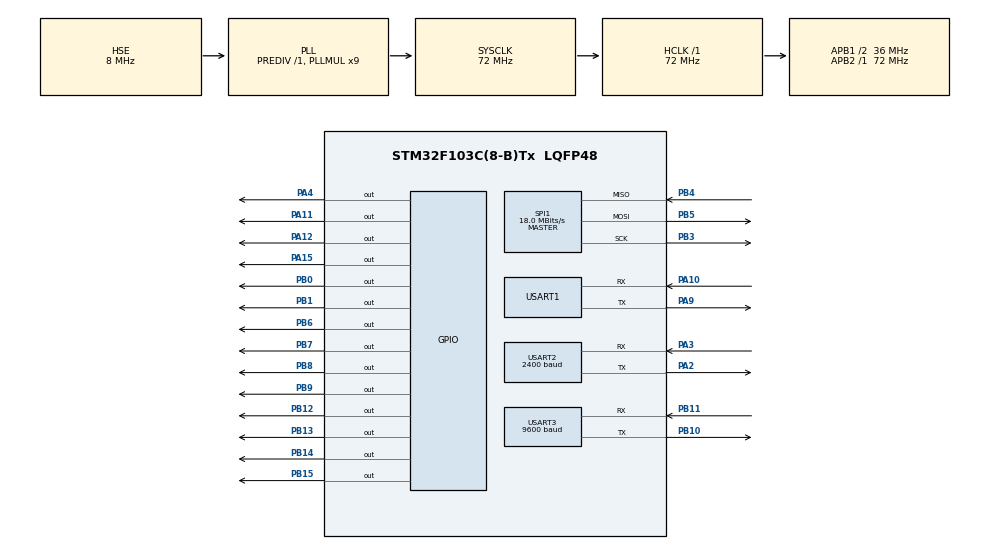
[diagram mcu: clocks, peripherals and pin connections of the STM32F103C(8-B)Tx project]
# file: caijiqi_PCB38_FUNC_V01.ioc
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Mcu.Family=STM32F1
Mcu.Name=STM32F103C(8-B)Tx
Mcu.Package=LQFP48
NVIC.PriorityGroup=NVIC_PRIORITYGROUP_2
NVIC.TIM1_UP_IRQn=true\:0\:0\:false\:false\:true\:true\:true
NVIC.USART1_IRQn=true\:0\:0\:true\:false\:true\:true\:true
NVIC.USART2_IRQn=true\:0\:0\:false\:false\:true\:true\:true
NVIC.USART3_IRQn=true\:0\:0\:false\:false\:true\:true\:true
PA10.Mode=Asynchronous
PA10.Signal=USART1_RX
PA11.Signal=GPIO_Output
PA12.Signal=GPIO_Output
PA13.Mode=Serial_Wire
PA13.Signal=SYS_JTMS-SWDIO
PA14.Mode=Serial_Wire
PA14.Signal=SYS_JTCK-SWCLK
PA15.Signal=GPIO_Output
PA2.Mode=Asynchronous
PA2.Signal=USART2_TX
PA3.Mode=Asynchronous
PA3.Signal=USART2_RX
PA4.Signal=GPIO_Output
PA9.Mode=Asynchronous
PA9.Signal=USART1_TX
PB0.Signal=GPIO_Output
PB1.Signal=GPIO_Output
PB10.Mode=Asynchronous
PB10.Signal=USART3_TX
PB11.Mode=Asynchronous
PB11.Signal=USART3_RX
PB12.Signal=GPIO_Output
PB13.Signal=GPIO_Output
PB14.GPIO_ModeDefaultOutputPP=GPIO_MODE_OUTPUT_OD
PB14.GPIO_PuPd=GPIO_PULLUP
PB14.GPIO_Speed=GPIO_SPEED_FREQ_HIGH
PB14.Signal=GPIO_Output
PB15.GPIO_ModeDefaultOutputPP=GPIO_MODE_OUTPUT_OD
PB15.GPIO_PuPd=GPIO_PULLUP
PB15.GPIO_Speed=GPIO_SPEED_FREQ_HIGH
PB15.Signal=GPIO_Output
PB3.Mode=Full_Duplex_Master
PB3.Signal=SPI1_SCK
PB4.Mode=Full_Duplex_Master
PB4.Signal=SPI1_MISO
PB5.Mode=Full_Duplex_Master
PB5.Signal=SPI1_MOSI
PB6.GPIO_Speed=GPIO_SPEED_FREQ_HIGH
PB6.PinState=GPIO_PIN_SET
PB6.Signal=GPIO_Output
PB7.GPIO_ModeDefaultOutputPP=GPIO_MODE_OUTPUT_OD
PB7.GPIO_PuPd=GPIO_PULLUP
PB7.Signal=GPIO_Output
PB8.Signal=GPIO_Output
PB9.Signal=GPIO_Output
PD0-OSC_IN.Mode=HSE-External-Oscillator
PD0-OSC_IN.Signal=RCC_OSC_IN
PD1-OSC_OUT.Mode=HSE-External-Oscillator
PD1-OSC_OUT.Signal=RCC_OSC_OUT
ProjectManager.HeapSize=0x400
ProjectManager.StackSize=0x400
ProjectManager.TargetToolchain=MDK-ARM V5
RCC.AHBFreq_Value=72000000
RCC.APB1CLKDivider=RCC_HCLK_DIV2
RCC.APB1Freq_Value=36000000
RCC.APB1TimFreq_Value=72000000
RCC.APB2Freq_Value=72000000
RCC.APB2TimFreq_Value=72000000
RCC.HCLKFreq_Value=72000000
RCC.PLLMUL=RCC_PLL_MUL9
RCC.PLLSourceVirtual=RCC_PLLSOURCE_HSE
RCC.SYSCLKFreq_VALUE=72000000
RCC.SYSCLKSource=RCC_SYSCLKSOURCE_PLLCLK
RCC.USBFreq_Value=72000000
SPI1.BaudRatePrescaler=SPI_BAUDRATEPRESCALER_4
SPI1.CLKPhase=SPI_PHASE_2EDGE
SPI1.CLKPolarity=SPI_POLARITY_HIGH
SPI1.CRCCalculation=SPI_CRCCALCULATION_DISABLE
SPI1.CalculateBaudRate=18.0 MBits/s
SPI1.Direction=SPI_DIRECTION_2LINES
SPI1.Mode=SPI_MODE_MASTER
SPI1.VirtualType=VM_MASTER
TIM1.ClockDivision=TIM_CLOCKDIVISION_DIV1
TIM1.Period=1000-1
TIM1.Prescaler=72-1
USART1.VirtualMode=VM_ASYNC
USART2.BaudRate=2400
USART2.Parity=PARITY_EVEN
USART2.VirtualMode=VM_ASYNC
USART2.WordLength=WORDLENGTH_9B
USART3.BaudRate=9600
USART3.VirtualMode=VM_ASYNC
VP_IWDG_VS_IWDG.Mode=IWDG_Activate
VP_TIM1_VS_ClockSourceINT.Mode=Internal
board=custom

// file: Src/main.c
/* USER CODE BEGIN Header */
/**
  ******************************************************************************
  * @file           : main.c
  * @brief          : Main program body
  ******************************************************************************
  * @attention
  *
  * <h2><center>&copy; Copyright (c) 2019 STMicroelectronics.
  * All rights reserved.</center></h2>
  *
  * This software component is licensed by ST under BSD 3-Clause license,
  * the "License"; You may not use this file except in compliance with the
  * License. You may obtain a copy of the License at:
  *                        opensource.org/licenses/BSD-3-Clause
  *
  ******************************************************************************
  */
/* USER CODE END Header */

#include "main.h"

IWDG_HandleTypeDef hiwdg;

SPI_HandleTypeDef hspi1;

TIM_HandleTypeDef htim1;

UART_HandleTypeDef huart1;
UART_HandleTypeDef huart2;
UART_HandleTypeDef huart3;

/* USER CODE BEGIN PV */
	void my_main(void);
/* USER CODE END PV */

void SystemClock_Config(void);
static void MX_GPIO_Init(void);
static void MX_USART1_UART_Init(void);
static void MX_USART2_UART_Init(void);
static void MX_USART3_UART_Init(void);
static void MX_SPI1_Init(void);
static void MX_TIM1_Init(void);
static void MX_IWDG_Init(void);

int main(void)
{

  /* MCU Configuration--------------------------------------------------------*/

  /* Reset of all peripherals, Initializes the Flash interface and the Systick. */
  HAL_Init();

  /* Configure the system clock */
  SystemClock_Config();

  /* Initialize all configured peripherals */
  MX_GPIO_Init();
  MX_USART1_UART_Init();
  MX_USART2_UART_Init();
  MX_USART3_UART_Init();
  MX_SPI1_Init();
  MX_TIM1_Init();
//  MX_IWDG_Init();
  /* USER CODE BEGIN 2 */
  my_main();
  /* USER CODE END 2 */

  /* Infinite loop */
  while (1)
  {

  }
}

void SystemClock_Config(void)
{
  RCC_OscInitTypeDef RCC_OscInitStruct = {0};
  RCC_ClkInitTypeDef RCC_ClkInitStruct = {0};

  /** Initializes the CPU, AHB and APB busses clocks
  */
  RCC_OscInitStruct.OscillatorType = RCC_OSCILLATORTYPE_LSI|RCC_OSCILLATORTYPE_HSE;
  RCC_OscInitStruct.HSEState = RCC_HSE_ON;
  RCC_OscInitStruct.HSEPredivValue = RCC_HSE_PREDIV_DIV1;
  RCC_OscInitStruct.HSIState = RCC_HSI_ON;
  RCC_OscInitStruct.LSIState = RCC_LSI_ON;
  RCC_OscInitStruct.PLL.PLLState = RCC_PLL_ON;
  RCC_OscInitStruct.PLL.PLLSource = RCC_PLLSOURCE_HSE;
  RCC_OscInitStruct.PLL.PLLMUL = RCC_PLL_MUL9;
  if (HAL_RCC_OscConfig(&RCC_OscInitStruct) != HAL_OK)
  {
    Error_Handler();
  }
  /** Initializes the CPU, AHB and APB busses clocks
  */
  RCC_ClkInitStruct.ClockType = RCC_CLOCKTYPE_HCLK|RCC_CLOCKTYPE_SYSCLK
                              |RCC_CLOCKTYPE_PCLK1|RCC_CLOCKTYPE_PCLK2;
  RCC_ClkInitStruct.SYSCLKSource = RCC_SYSCLKSOURCE_PLLCLK;
  RCC_ClkInitStruct.AHBCLKDivider = RCC_SYSCLK_DIV1;
  RCC_ClkInitStruct.APB1CLKDivider = RCC_HCLK_DIV2;
  RCC_ClkInitStruct.APB2CLKDivider = RCC_HCLK_DIV1;

  if (HAL_RCC_ClockConfig(&RCC_ClkInitStruct, FLASH_LATENCY_2) != HAL_OK)
  {
    Error_Handler();
  }
}

static void MX_IWDG_Init(void)
{

  hiwdg.Instance = IWDG;
  hiwdg.Init.Prescaler = IWDG_PRESCALER_4;
  hiwdg.Init.Reload = 4095;
  if (HAL_IWDG_Init(&hiwdg) != HAL_OK)
  {
    Error_Handler();
  }

}

static void MX_SPI1_Init(void)
{

  /* SPI1 parameter configuration*/
  hspi1.Instance = SPI1;
  hspi1.Init.Mode = SPI_MODE_MASTER;
  hspi1.Init.Direction = SPI_DIRECTION_2LINES;
  hspi1.Init.DataSize = SPI_DATASIZE_8BIT;
  hspi1.Init.CLKPolarity = SPI_POLARITY_HIGH;
  hspi1.Init.CLKPhase = SPI_PHASE_2EDGE;
  hspi1.Init.NSS = SPI_NSS_SOFT;
  hspi1.Init.BaudRatePrescaler = SPI_BAUDRATEPRESCALER_4;
  hspi1.Init.FirstBit = SPI_FIRSTBIT_MSB;
  hspi1.Init.TIMode = SPI_TIMODE_DISABLE;
  hspi1.Init.CRCCalculation = SPI_CRCCALCULATION_DISABLE;
  hspi1.Init.CRCPolynomial = 10;
  if (HAL_SPI_Init(&hspi1) != HAL_OK)
  {
    Error_Handler();
  }

}

static void MX_TIM1_Init(void)
{

  TIM_ClockConfigTypeDef sClockSourceConfig = {0};
  TIM_MasterConfigTypeDef sMasterConfig = {0};

  htim1.Instance = TIM1;
  htim1.Init.Prescaler = 72-1;
  htim1.Init.CounterMode = TIM_COUNTERMODE_UP;
  htim1.Init.Period = 1000-1;
  htim1.Init.ClockDivision = TIM_CLOCKDIVISION_DIV1;
  htim1.Init.RepetitionCounter = 0;
  htim1.Init.AutoReloadPreload = TIM_AUTORELOAD_PRELOAD_DISABLE;
  if (HAL_TIM_Base_Init(&htim1) != HAL_OK)
  {
    Error_Handler();
  }
  sClockSourceConfig.ClockSource = TIM_CLOCKSOURCE_INTERNAL;
  if (HAL_TIM_ConfigClockSource(&htim1, &sClockSourceConfig) != HAL_OK)
  {
    Error_Handler();
  }
  sMasterConfig.MasterOutputTrigger = TIM_TRGO_RESET;
  sMasterConfig.MasterSlaveMode = TIM_MASTERSLAVEMODE_DISABLE;
  if (HAL_TIMEx_MasterConfigSynchronization(&htim1, &sMasterConfig) != HAL_OK)
  {
    Error_Handler();
  }
  /* USER CODE BEGIN TIM1_Init 2 */
  // TIM_ClockConfigTypeDef sClockSourceConfig;
  // TIM_MasterConfigTypeDef sMasterConfig;

  // htim1.Instance = TIM1;
  // htim1.Init.Prescaler = 36-1;
  // htim1.Init.CounterMode = TIM_COUNTERMODE_UP;
  // htim1.Init.Period = 1000;
  // htim1.Init.ClockDivision = TIM_CLOCKDIVISION_DIV1;
  // htim1.Init.AutoReloadPreload = TIM_AUTORELOAD_PRELOAD_DISABLE;
  // if (HAL_TIM_Base_Init(&htim1) != HAL_OK)
  // {
  //   Error_Handler();
  // }

  // sClockSourceConfig.ClockSource = TIM_CLOCKSOURCE_INTERNAL;
  // if (HAL_TIM_ConfigClockSource(&htim1, &sClockSourceConfig) != HAL_OK)
  // {
  //   Error_Handler();
  // }

  // sMasterConfig.MasterOutputTrigger = TIM_TRGO_RESET;
  // sMasterConfig.MasterSlaveMode = TIM_MASTERSLAVEMODE_DISABLE;
  // if (HAL_TIMEx_MasterConfigSynchronization(&htim1, &sMasterConfig) != HAL_OK)
  // {
  //   Error_Handler();
  // }
  /* USER CODE END TIM1_Init 2 */

}

static void MX_USART1_UART_Init(void)
{

  huart1.Instance = USART1;
  huart1.Init.BaudRate = 115200;
  huart1.Init.WordLength = UART_WORDLENGTH_8B;
  huart1.Init.StopBits = UART_STOPBITS_1;
  huart1.Init.Parity = UART_PARITY_NONE;
  huart1.Init.Mode = UART_MODE_TX_RX;
  huart1.Init.HwFlowCtl = UART_HWCONTROL_NONE;
  huart1.Init.OverSampling = UART_OVERSAMPLING_16;
  if (HAL_UART_Init(&huart1) != HAL_OK)
  {
    Error_Handler();
  }

}

static void MX_USART2_UART_Init(void)
{

  huart2.Instance = USART2;
  huart2.Init.BaudRate = 2400;
  huart2.Init.WordLength = UART_WORDLENGTH_9B;
  huart2.Init.StopBits = UART_STOPBITS_1;
  huart2.Init.Parity = UART_PARITY_EVEN;
  huart2.Init.Mode = UART_MODE_TX_RX;
  huart2.Init.HwFlowCtl = UART_HWCONTROL_NONE;
  huart2.Init.OverSampling = UART_OVERSAMPLING_16;
  if (HAL_UART_Init(&huart2) != HAL_OK)
  {
    Error_Handler();
  }

}

static void MX_USART3_UART_Init(void)
{

  huart3.Instance = USART3;
  huart3.Init.BaudRate = 115200;
  huart3.Init.WordLength = UART_WORDLENGTH_8B;
  huart3.Init.StopBits = UART_STOPBITS_1;
  huart3.Init.Parity = UART_PARITY_NONE;
  huart3.Init.Mode = UART_MODE_TX_RX;
  huart3.Init.HwFlowCtl = UART_HWCONTROL_NONE;
  huart3.Init.OverSampling = UART_OVERSAMPLING_16;
  if (HAL_UART_Init(&huart3) != HAL_OK)
  {
    Error_Handler();
  }

}

static void MX_GPIO_Init(void)
{
  GPIO_InitTypeDef GPIO_InitStruct = {0};

  /* GPIO Ports Clock Enable */
  __HAL_RCC_GPIOD_CLK_ENABLE();
  __HAL_RCC_GPIOA_CLK_ENABLE();
  __HAL_RCC_GPIOB_CLK_ENABLE();

  /*Configure GPIO pin Output Level */
  HAL_GPIO_WritePin(GPIOA, GPIO_PIN_4|GPIO_PIN_11|GPIO_PIN_12|GPIO_PIN_15, GPIO_PIN_RESET);

  /*Configure GPIO pin Output Level */
  HAL_GPIO_WritePin(GPIOB, GPIO_PIN_0|GPIO_PIN_1|GPIO_PIN_12|GPIO_PIN_13
                          |GPIO_PIN_14|GPIO_PIN_15|GPIO_PIN_7|GPIO_PIN_8
                          |GPIO_PIN_9, GPIO_PIN_RESET);

  /*Configure GPIO pin Output Level */
  HAL_GPIO_WritePin(GPIOB, GPIO_PIN_6, GPIO_PIN_SET);

  /*Configure GPIO pins : PA4 PA11 PA12 PA15 */
  GPIO_InitStruct.Pin = GPIO_PIN_4|GPIO_PIN_11|GPIO_PIN_12|GPIO_PIN_15;
  GPIO_InitStruct.Mode = GPIO_MODE_OUTPUT_PP;
  GPIO_InitStruct.Pull = GPIO_NOPULL;
  GPIO_InitStruct.Speed = GPIO_SPEED_FREQ_LOW;
  HAL_GPIO_Init(GPIOA, &GPIO_InitStruct);

  /*Configure GPIO pins : PB0 PB1 PB12 PB13
                           PB8 PB9 */
  GPIO_InitStruct.Pin = GPIO_PIN_0|GPIO_PIN_1|GPIO_PIN_12|GPIO_PIN_13
                          |GPIO_PIN_8|GPIO_PIN_9;
  GPIO_InitStruct.Mode = GPIO_MODE_OUTPUT_PP;
  GPIO_InitStruct.Pull = GPIO_NOPULL;
  GPIO_InitStruct.Speed = GPIO_SPEED_FREQ_LOW;
  HAL_GPIO_Init(GPIOB, &GPIO_InitStruct);

  /*Configure GPIO pins : PB14 PB15 */
  GPIO_InitStruct.Pin = GPIO_PIN_14|GPIO_PIN_15;
  GPIO_InitStruct.Mode = GPIO_MODE_OUTPUT_OD;
  GPIO_InitStruct.Pull = GPIO_PULLUP;
  GPIO_InitStruct.Speed = GPIO_SPEED_FREQ_HIGH;
  HAL_GPIO_Init(GPIOB, &GPIO_InitStruct);

  /*Configure GPIO pin : PB6 */
  GPIO_InitStruct.Pin = GPIO_PIN_6;
  GPIO_InitStruct.Mode = GPIO_MODE_OUTPUT_PP;
  GPIO_InitStruct.Pull = GPIO_NOPULL;
  GPIO_InitStruct.Speed = GPIO_SPEED_FREQ_HIGH;
  HAL_GPIO_Init(GPIOB, &GPIO_InitStruct);

  /*Configure GPIO pin : PB7 */
  GPIO_InitStruct.Pin = GPIO_PIN_7;
  GPIO_InitStruct.Mode = GPIO_MODE_OUTPUT_OD;
  GPIO_InitStruct.Pull = GPIO_PULLUP;
  GPIO_InitStruct.Speed = GPIO_SPEED_FREQ_LOW;
  HAL_GPIO_Init(GPIOB, &GPIO_InitStruct);

}

void Error_Handler(void)
{
}

/************************ (C) COPYRIGHT STMicroelectronics *****END OF FILE****/
